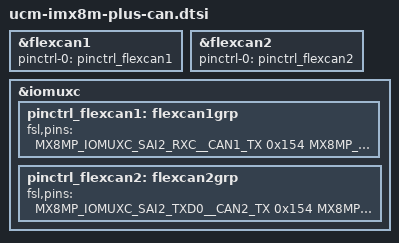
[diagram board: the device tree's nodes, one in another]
/*
 * Copyright 2022 CompuLab
 *
 * This program is free software; you can redistribute it and/or
 * modify it under the terms of the GNU General Public License
 * as published by the Free Software Foundation; either version 2
 * of the License, or (at your option) any later version.
 *
 * This program is distributed in the hope that it will be useful,
 * but WITHOUT ANY WARRANTY; without even the implied warranty of
 * MERCHANTABILITY or FITNESS FOR A PARTICULAR PURPOSE.  See the
 * GNU General Public License for more details.
 */

&flexcan1 {
	pinctrl-names = "default";
	pinctrl-0 = <&pinctrl_flexcan1>;
};

&flexcan2 {
	pinctrl-names = "default";
	pinctrl-0 = <&pinctrl_flexcan2>;
};

&iomuxc {
	pinctrl_flexcan1: flexcan1grp {
		fsl,pins = <
			MX8MP_IOMUXC_SAI2_RXC__CAN1_TX			0x154
			MX8MP_IOMUXC_SAI2_TXC__CAN1_RX			0x154
		>;
	};

	pinctrl_flexcan2: flexcan2grp {
		fsl,pins = <
			MX8MP_IOMUXC_SAI2_TXD0__CAN2_TX			0x154
			MX8MP_IOMUXC_SAI2_MCLK__CAN2_RX			0x154
		>;
	};
};
